# STM32F410 register map
File version: 1.8
CPU: CM4 r0p1, little endian, MPU, FPU, 4 interrupt priority bits
Registers are 32-bit, read-write, reset 0x0 unless marked. A register's access mark holds for its fields unless they carry their own. Offsets are from the block's base; [hi:lo] are bit positions; {n}, {i} and the like mark numbered series; 'fields as' and 'values as' point back to an identical list.

## RCC — Reset and clock control
Base 0x40023800
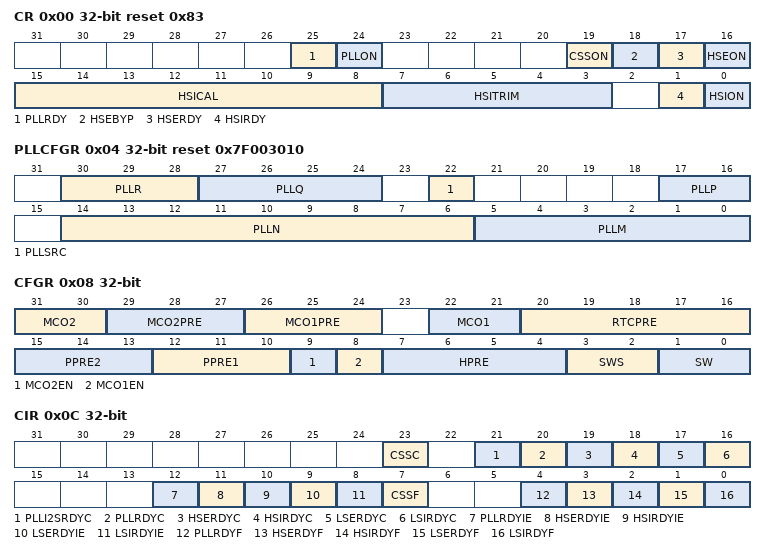
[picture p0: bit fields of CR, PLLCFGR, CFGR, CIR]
0x00 CR access per field reset 0x83 — clock control register
  [25] PLLRDY ro — Main PLL (PLL) clock ready flag
    0=NotReady (Clock not ready); 1=Ready (Clock ready)
  [24] PLLON rw — Main PLL (PLL) enable
    0=Off (Clock Off); 1=On (Clock On)
  [19] CSSON rw — Clock security system enable
    0=Off (Clock security system disabled (clock detector OFF)); 1=On (Clock security system enable (clock detector ON if the HSE is ready, OFF if not))
  [18] HSEBYP rw — HSE clock bypass
    0=NotBypassed (HSE crystal oscillator not bypassed); 1=Bypassed (HSE crystal oscillator bypassed with external clock)
  [17] HSERDY ro — HSE clock ready flag
    0=NotReady (Clock not ready); 1=Ready (Clock ready)
  [16] HSEON rw — HSE clock enable
    0=Off (Clock Off); 1=On (Clock On)
  [15:8] HSICAL ro — Internal high-speed clock calibration
  [7:3] HSITRIM rw — Internal high-speed clock trimming
  [1] HSIRDY ro — Internal high-speed clock ready flag
    0=NotReady (Clock not ready); 1=Ready (Clock ready)
  [0] HSION rw — Internal high-speed clock enable
    0=Off (Clock Off); 1=On (Clock On)
0x04 PLLCFGR reset 0x7F003010 — PLL configuration register
  [30:28] PLLR range 2..7 — PLL division factor for I2S and System clocks
  [27:24] PLLQ range 2..15 — Main PLL (PLL) division factor for USB OTG FS, SDIO and random number generator clocks
  [22] PLLSRC — Main PLL(PLL) and audio PLL (PLLI2S) entry clock source
    0=HSI (HSI clock selected as PLL and PLLI2S clock entry); 1=HSE (HSE oscillator clock selected as PLL and PLLI2S clock entry)
  [17:16] PLLP — Main PLL (PLL) division factor for main system clock
    0=Div2 (PLLP=2); 1=Div4 (PLLP=4); 2=Div6 (PLLP=6); 3=Div8 (PLLP=8)
  [14:6] PLLN range 50..432 — Main PLL (PLL) multiplication factor for VCO
  [5:0] PLLM range 2..63 — Division factor for the main PLL (PLL) and audio PLL (PLLI2S) input clock
0x08 CFGR access not given — clock configuration register
  [31:30] MCO2 rw — Microcontroller clock output 2
    0=SYSCLK (System clock (SYSCLK) selected); 1=PLLI2S (PLLI2S clock selected); 2=HSE (HSE oscillator clock selected); 3=PLL (PLL clock selected)
  [29:27] MCO2PRE rw — MCO2 prescaler
    {v}=Div{v-2} (Division by {v-2}) (v=4..7); other=Div1 (No division)
  [26:24] MCO1PRE rw — MCO1 prescaler
    values as MCO2PRE
  [22:21] MCO1 rw — Microcontroller clock output 1
    0=HSI (HSI clock selected); 1=LSE (LSE oscillator selected); 2=HSE (HSE oscillator clock selected); 3=PLL (PLL clock selected)
  [20:16] RTCPRE rw — HSE division factor for RTC clock
  [15:13] PPRE2 rw — APB high-speed prescaler (APB2)
    4=Div2 (HCLK divided by 2); 5=Div4 (HCLK divided by 4); 6=Div8 (HCLK divided by 8); 7=Div16 (HCLK divided by 16); other=Div1 (HCLK not divided)
  [12:10] PPRE1 rw — APB Low speed prescaler (APB1)
    values as PPRE2
  [9] MCO2EN rw — MCO output enable
    0=Disabled (MCO output disabled); 1=Enabled (MCO output enabled)
  [8] MCO1EN rw — MCO output enable
    values as MCO2EN
  [7:4] HPRE rw — AHB prescaler
    8=Div2 (SYSCLK divided by 2); 9=Div4 (SYSCLK divided by 4); 10=Div8 (SYSCLK divided by 8); 11=Div16 (SYSCLK divided by 16); 12=Div64 (SYSCLK divided by 64); 13=Div128 (SYSCLK divided by 128); 14=Div256 (SYSCLK divided by 256); 15=Div512 (SYSCLK divided by 512); other=Div1 (SYSCLK not divided)
  [3:2] SWS — System clock switch status
    on read: 0=HSI (HSI oscillator used as system clock); 1=HSE (HSE oscillator used as system clock); 2=PLL (PLL used as system clock)
  [1:0] SW — System clock switch
    0=HSI (HSI selected as system clock); 1=HSE (HSE selected as system clock); 2=PLL (PLL selected as system clock)
0x0C CIR access per field — clock interrupt register
  [23] CSSC wo — Clock security system interrupt clear
    1=Clear CSSF flag
  [21] PLLI2SRDYC wo — PLLI2S ready interrupt clear
    1=Clear interrupt flag
  [20] PLLRDYC wo — Main PLL(PLL) ready interrupt clear
    1=Clear interrupt flag
  [19] HSERDYC wo — HSE ready interrupt clear
    1=Clear interrupt flag
  [18] HSIRDYC wo — HSI ready interrupt clear
    1=Clear interrupt flag
  [17] LSERDYC wo — LSE ready interrupt clear
    1=Clear interrupt flag
  [16] LSIRDYC wo — LSI ready interrupt clear
    1=Clear interrupt flag
  [12] PLLRDYIE rw — Main PLL (PLL) ready interrupt enable
    0=Disabled (Interrupt disabled); 1=Enabled (Interrupt enabled)
  [11] HSERDYIE rw — HSE ready interrupt enable
    values as PLLRDYIE
  [10] HSIRDYIE rw — HSI ready interrupt enable
    values as PLLRDYIE
  [9] LSERDYIE rw — LSE ready interrupt enable
    values as PLLRDYIE
  [8] LSIRDYIE rw — LSI ready interrupt enable
    values as PLLRDYIE
  [7] CSSF ro — Clock security system interrupt flag
    0=NotInterrupted (No clock security interrupt caused by HSE clock failure); 1=Interrupted (Clock security interrupt caused by HSE clock failure)
  [4] PLLRDYF ro — Main PLL (PLL) ready interrupt flag
    0=NotInterrupted (No clock ready interrupt); 1=Interrupted (Clock ready interrupt)
  [3] HSERDYF ro — HSE ready interrupt flag
    values as PLLRDYF
  [2] HSIRDYF ro — HSI ready interrupt flag
    values as PLLRDYF
  [1] LSERDYF ro — LSE ready interrupt flag
    values as PLLRDYF
  [0] LSIRDYF ro — LSI ready interrupt flag
    values as PLLRDYF
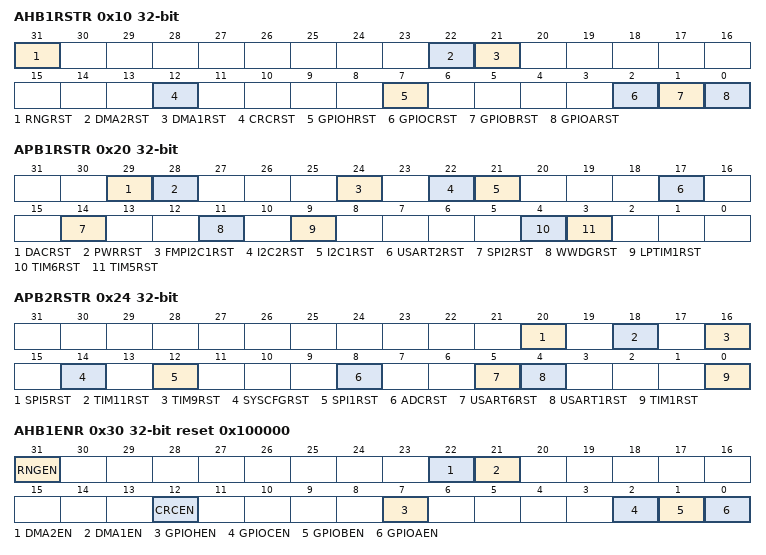
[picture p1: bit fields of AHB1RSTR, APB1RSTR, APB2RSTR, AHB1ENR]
0x10 AHB1RSTR — AHB1 peripheral reset register
  [all] fields
    1=Reset the selected module
  [31] RNGRST
  [22] DMA2RST — DMA2 reset
  [21] DMA1RST — DMA2 reset
  [12] CRCRST — CRC reset
  [7] GPIOHRST — IO port H reset
  [2] GPIOCRST — IO port C reset
  [1] GPIOBRST — IO port B reset
  [0] GPIOARST — IO port A reset
0x20 APB1RSTR — APB1 peripheral reset register
  [all] fields
    1=Reset the selected module
  [29] DACRST — DAC reset
  [28] PWRRST — Power interface reset
  [24] FMPI2C1RST — FMPI2C1 reset
  [22] I2C2RST — I2C 2 reset
  [21] I2C1RST — I2C 1 reset
  [17] USART2RST — USART 2 reset
  [14] SPI2RST — SPI 2 reset
  [11] WWDGRST — Window watchdog reset
  [9] LPTIM1RST — LPTIM1 reset
  [4] TIM6RST — TIM6 reset
  [3] TIM5RST — TIM5 reset
0x24 APB2RSTR — APB2 peripheral reset register
  [all] fields
    1=Reset the selected module
  [20] SPI5RST — SPI5 reset
  [18] TIM11RST — TIM11 reset
  [16] TIM9RST — TIM9 reset
  [14] SYSCFGRST — System configuration controller reset
  [12] SPI1RST — SPI 1 reset
  [8] ADCRST — ADC interface reset (common to all ADCs)
  [5] USART6RST — USART6 reset
  [4] USART1RST — USART1 reset
  [0] TIM1RST — TIM1 reset
0x30 AHB1ENR reset 0x100000 — AHB1 peripheral clock register
  [all] fields
    0=Disabled (The selected clock is disabled); 1=Enabled (The selected clock is enabled)
  [31] RNGEN — RNG clock enable
  [22] DMA2EN — DMA2 clock enable
  [21] DMA1EN — DMA1 clock enable
  [12] CRCEN — CRC clock enable
  [7] GPIOHEN — IO port H clock enable
  [2] GPIOCEN — IO port C clock enable
  [1] GPIOBEN — IO port B clock enable
  [0] GPIOAEN — IO port A clock enable
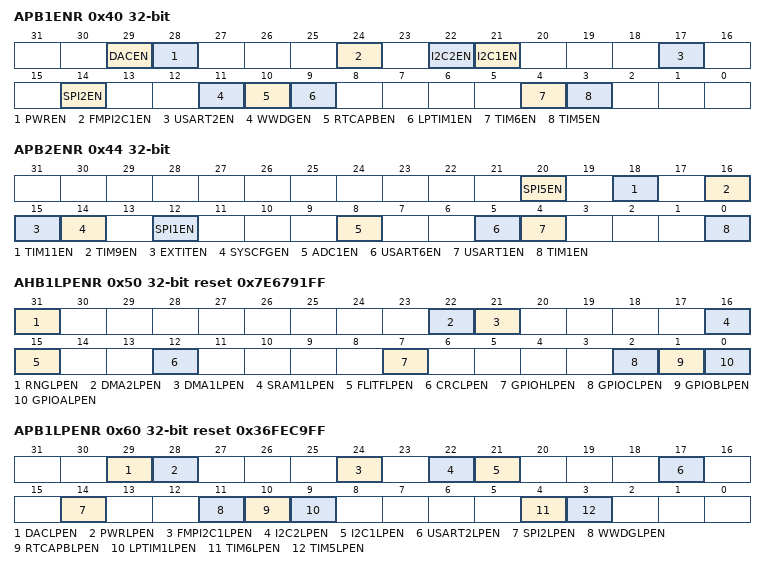
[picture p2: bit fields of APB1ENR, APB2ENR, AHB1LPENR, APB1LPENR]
0x40 APB1ENR — APB1 peripheral clock enable register
  [all] fields
    values as the fields of AHB1ENR
  [29] DACEN — DAC interface clock enable
  [28] PWREN — Power interface clock enable
  [24] FMPI2C1EN — FMPI2C1 clock enable
  [22] I2C2EN — I2C2 clock enable
  [21] I2C1EN — I2C1 clock enable
  [17] USART2EN — USART 2 clock enable
  [14] SPI2EN — SPI2 clock enable
  [11] WWDGEN — Window watchdog clock enable
  [10] RTCAPBEN — RTC APB clock enable
  [9] LPTIM1EN — LPTIM1 clock enable
  [4] TIM6EN — TIM6 clock enable
  [3] TIM5EN — TIM5 clock enable
0x44 APB2ENR — APB2 peripheral clock enable register
  [all] fields
    values as the fields of AHB1ENR
  [20] SPI5EN — SPI5 clock enable
  [18] TIM11EN — TIM11 clock enable
  [16] TIM9EN — TIM9 clock enable
  [15] EXTITEN — EXTI ans external IT clock enable
  [14] SYSCFGEN — System configuration controller clock enable
  [12] SPI1EN — SPI1 clock enable
  [8] ADC1EN — ADC1 clock enable
  [5] USART6EN — USART6 clock enable
  [4] USART1EN — USART1 clock enable
  [0] TIM1EN — TIM1 clock enable
0x50 AHB1LPENR reset 0x7E6791FF — AHB1 peripheral clock enable in low power mode register
  [all] fields
    0=DisabledInSleep (Selected module is disabled during Sleep mode); 1=EnabledInSleep (Selected module is enabled during Sleep mode)
  [31] RNGLPEN — RNG clock enable during sleep mode
  [22] DMA2LPEN — DMA2 clock enable during Sleep mode
  [21] DMA1LPEN — DMA1 clock enable during Sleep mode
  [16] SRAM1LPEN — SRAM 1interface clock enable during Sleep mode
  [15] FLITFLPEN — Flash interface clock enable during Sleep mode
  [12] CRCLPEN — CRC clock enable during Sleep mode
  [7] GPIOHLPEN — IO port H clock enable during Sleep mode
  [2] GPIOCLPEN — IO port C clock enable during Sleep mode
  [1] GPIOBLPEN — IO port B clock enable during Sleep mode
  [0] GPIOALPEN — IO port A clock enable during sleep mode
0x60 APB1LPENR reset 0x36FEC9FF — APB1 peripheral clock enable in low power mode register
  [all] fields
    values as the fields of AHB1LPENR
  [29] DACLPEN — DAC interface clock enable during sleep mode
  [28] PWRLPEN — Power interface clock enable during Sleep mode
  [24] FMPI2C1LPEN — FMPI2C1 clock enable during Sleep
  [22] I2C2LPEN — I2C2 clock enable during Sleep mode
  [21] I2C1LPEN — I2C1 clock enable during Sleep mode
  [17] USART2LPEN — USART2 clock enable during Sleep mode
  [14] SPI2LPEN — SPI2 clock enable during Sleep mode
  [11] WWDGLPEN — Window watchdog clock enable during Sleep mode
  [10] RTCAPBLPEN — RTC APB clock enable during sleep mode
  [9] LPTIM1LPEN — LPTIM1 clock enable during sleep mode
  [4] TIM6LPEN — TIM6 clock enable during Sleep mode
  [3] TIM5LPEN — TIM5 clock enable during Sleep mode
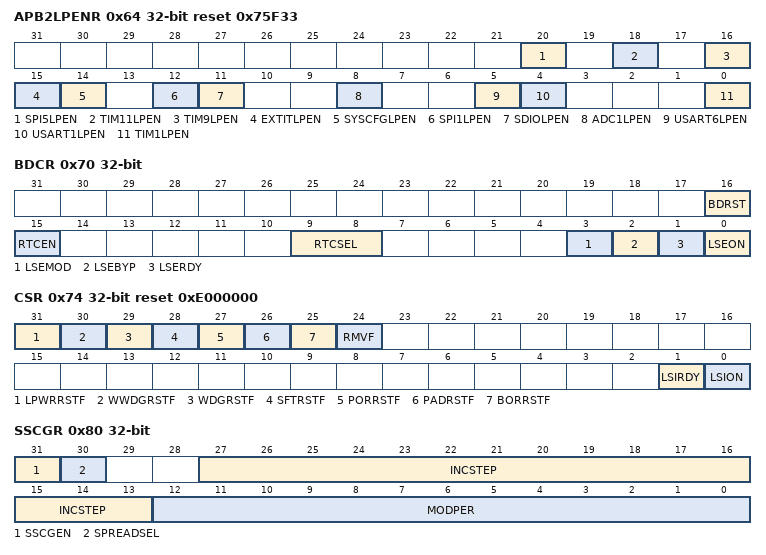
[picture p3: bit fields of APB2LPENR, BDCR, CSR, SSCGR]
0x64 APB2LPENR reset 0x75F33 — APB2 peripheral clock enabled in low power mode register
  [all] fields
    values as the fields of AHB1LPENR
  [20] SPI5LPEN — SPI5 clock enable during Sleep mode
  [18] TIM11LPEN — TIM11 clock enable during Sleep mode
  [16] TIM9LPEN — TIM9 clock enable during sleep mode
  [15] EXTITLPEN — EXTI and External IT clock enable during sleep mode
  [14] SYSCFGLPEN — System configuration controller clock enable during Sleep mode
  [12] SPI1LPEN — SPI 1 clock enable during Sleep mode
  [11] SDIOLPEN — SDIO clock enable during Sleep mode
  [8] ADC1LPEN — ADC1 clock enable during Sleep mode
  [5] USART6LPEN — USART6 clock enable during Sleep mode
  [4] USART1LPEN — USART1 clock enable during Sleep mode
  [0] TIM1LPEN — TIM1 clock enable during Sleep mode
0x70 BDCR access not given — Backup domain control register
  [16] BDRST rw — Backup domain software reset
    0=Disabled (Reset not activated); 1=Enabled (Reset the entire RTC domain)
  [15] RTCEN rw — RTC clock enable
    0=Disabled (RTC clock disabled); 1=Enabled (RTC clock enabled)
  [9:8] RTCSEL — RTC clock source selection
    0=NoClock; 1=LSE (LSE oscillator clock used as RTC clock); 2=LSI (LSI oscillator clock used as RTC clock); 3=HSE (HSE oscillator clock divided by a prescaler used as RTC clock)
  [3] LSEMOD — External low speed oscillator
    0=Low (LSE oscillator low power mode selection); 1=High (LSE oscillator high drive mode selection)
  [2] LSEBYP rw — External low-speed oscillator bypass
    0=NotBypassed (LSE crystal oscillator not bypassed); 1=Bypassed (LSE crystal oscillator bypassed with external clock)
  [1] LSERDY ro — External low-speed oscillator ready
    0=NotReady (LSE oscillator not ready); 1=Ready (LSE oscillator ready)
  [0] LSEON rw — External low-speed oscillator enable
    0=Off (LSE oscillator Off); 1=On (LSE oscillator On)
0x74 CSR access per field reset 0xE000000 — clock control & status register
  [31] LPWRRSTF rw — Low-power reset flag
    on read: 0=No reset has occured; 1=Reset (A reset has occured)
  [30] WWDGRSTF rw — Window watchdog reset flag
    values as LPWRRSTF
  [29] WDGRSTF rw — Independent watchdog reset flag
    values as LPWRRSTF
  [28] SFTRSTF rw — Software reset flag
    values as LPWRRSTF
  [27] PORRSTF rw — POR/PDR reset flag
    values as LPWRRSTF
  [26] PADRSTF rw — PIN reset flag
    values as LPWRRSTF
  [25] BORRSTF rw — BOR reset flag
    values as LPWRRSTF
  [24] RMVF rw — Remove reset flag
    on write: 1=Clears the reset flag
  [1] LSIRDY ro — Internal low-speed oscillator ready
    0=NotReady (LSI oscillator not ready); 1=Ready (LSI oscillator ready)
  [0] LSION rw — Internal low-speed oscillator enable
    0=Off (LSI oscillator Off); 1=On (LSI oscillator On)
0x80 SSCGR — spread spectrum clock generation register
  [31] SSCGEN — Spread spectrum modulation enable
    0=Disabled (Spread spectrum modulation disabled); 1=Enabled (Spread spectrum modulation enabled)
  [30] SPREADSEL — Spread Select
    0=Center spread; 1=Down spread
  [27:13] INCSTEP — Incrementation step
  [12:0] MODPER — Modulation period
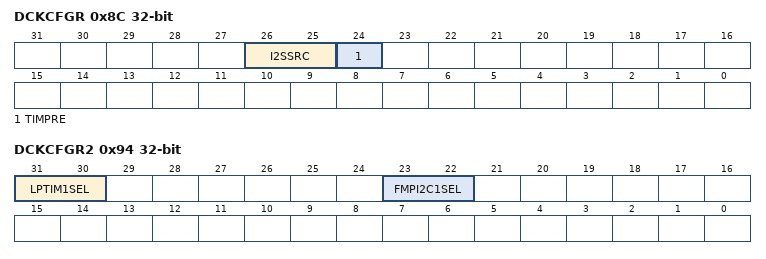
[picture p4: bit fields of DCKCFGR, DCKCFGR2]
0x8C DCKCFGR
  [26:25] I2SSRC
    0=PLLCLKR (I2Sx clock frequency = f(PLLCLK_R)); 1=I2S_CKIN (I2Sx clock frequency = I2S_CKIN Alternate function input frequency); 3=HSI_HSE (I2Sx clock frequency = HSI/HSE depends on PLLSRC bit (PLLCFGR[22]))
  [24] TIMPRE
    0=Mul1Or2 (If the APB prescaler is configured 1, TIMxCLK = PCLKx. Otherwise, TIMxCLK = 2xPCLKx); 1=Mul1Or4 (If the APB prescaler is configured 1, 2 or 4, TIMxCLK = HCLK. Otherwise, TIMxCLK = 4xPCLKx)
0x94 DCKCFGR2
  [31:30] LPTIM1SEL
    0=APB1 (APB1 clock (PCLK1) selected as LPTILM1 clock); 1=LSI (LSI clock is selected as LPTILM1 clock); 2=HSI (HSI clock is selected as LPTILM1 clock); 3=LSE (LSE clock is selected as LPTILM1 clock)
  [23:22] FMPI2C1SEL — FMPI2C1 kernel clock source selection
    0=APB (APB clock selected as I2C clock); 1=SYSCLK (System clock selected as I2C clock); 2=HSI (HSI clock selected as I2C clock)
